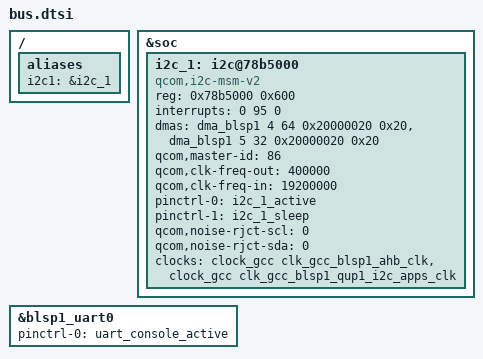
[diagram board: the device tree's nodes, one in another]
/* Copyright (c) 2018, Motorola Mobility Inc. All rights reserved.
 *
 * This program is free software; you can redistribute it and/or modify
 * it under the terms of the GNU General Public License version 2 and
 * only version 2 as published by the Free Software Foundation.
 *
 * This program is distributed in the hope that it will be useful,
 * but WITHOUT ANY WARRANTY; without even the implied warranty of
 * MERCHANTABILITY or FITNESS FOR A PARTICULAR PURPOSE.  See the
 * GNU General Public License for more details.
 */

&soc {
        i2c_1: i2c@78b5000 {
                compatible = "qcom,i2c-msm-v2";
                #address-cells = <1>;
                #size-cells = <0>;
                reg-names = "qup_phys_addr";
                reg = <0x78b5000 0x600>;
                interrupt-names = "qup_irq";
                interrupts = <0 95 0>;
                dmas = <&dma_blsp1 4 64 0x20000020 0x20>,
                        <&dma_blsp1 5 32 0x20000020 0x20>;
                dma-names = "tx", "rx";
                qcom,master-id = <86>;
                qcom,clk-freq-out = <400000>;
                qcom,clk-freq-in  = <19200000>;
                pinctrl-names = "i2c_active", "i2c_sleep";
                pinctrl-0 = <&i2c_1_active>;
                pinctrl-1 = <&i2c_1_sleep>;
                qcom,noise-rjct-scl = <0>;
                qcom,noise-rjct-sda = <0>;
                clock-names = "iface_clk", "core_clk";
                clocks = <&clock_gcc clk_gcc_blsp1_ahb_clk>,
                         <&clock_gcc clk_gcc_blsp1_qup1_i2c_apps_clk>;
        };
};

&blsp1_uart0 {
        status = "ok";
        pinctrl-names = "default";
        pinctrl-0 = <&uart_console_active>;
};

/ {
        aliases {
                i2c1 = &i2c_1;
                /delete-property/ spi3;
        };
};
